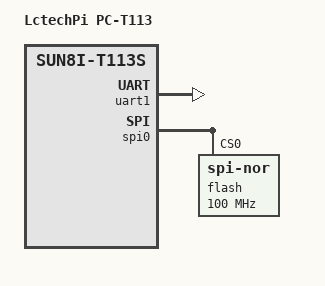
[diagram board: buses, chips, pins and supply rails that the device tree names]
// SPDX-License-Identifier: (GPL-2.0+ OR MIT)
// Copyright (C) 2023 Maksim Kiselev <bigunclemax@gmail.com>

/dts-v1/;

#include "sun8i-t113s-mangopi-mq-r-t113.dts"

/ {
	model = "LctechPi PC-T113";
	compatible = "widora,mangopi-mq-r-t113", "allwinner,sun8i-t113s";

	aliases {
		serial1 = &uart1;
	};

	chosen {
		stdout-path = "serial1:115200n8";
	};
};

&uart1 {
	pinctrl-names = "default";
	pinctrl-0 = <&uart1_pg6_pins>;
	status = "okay";
};

&spi0 {
	pinctrl-names = "default";
	pinctrl-0 = <&spi0_pins>;
	status = "okay";

	flash@0 { /* W25Q128JVEI */
		compatible = "jedec,spi-nor";
		reg = <0>;
		spi-max-frequency = <100000000>; /* Up to 133 MHz */
		spi-tx-bus-width = <1>;
		spi-rx-bus-width = <1>;
	};
};
